AUTOSAR XML (schema 4-2-2)
package /Components
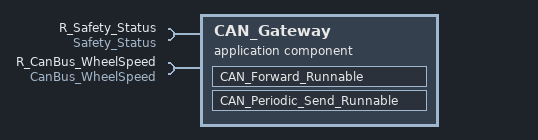
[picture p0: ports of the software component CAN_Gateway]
  application sw component type CAN_Gateway
    provide/require port PR_CAN_Gateway_Interface: provided-required-interface=CAN_Gateway_Interface
    provide/require port PR_BrakeActuator_Service: provided-required-interface=BrakeActuator_Service
    provide/require port PR_SteeringMotor_Service: provided-required-interface=SteeringMotor_Service
    require port R_Safety_Status: required-interface=Safety_Status
    require port R_CanBus_WheelSpeed: required-interface=CanBus_WheelSpeed
    behavior CAN_Gateway_Behavior
      data received event CAN_Rx_Event: start-on-event=CAN_Forward_Runnable
      data send completed event CAN_Tx_Complete: start-on-event=CAN_Periodic_Send_Runnable, event-source=CAN_Tx_Access
      runnable CAN_Forward_Runnable: symbol=Can_Gateway_CAN_Forward_Runnable
        data-receive-point-by-arguments:
          access CAN_Rx_Access: accessed-variable=PR_CAN_Gateway_Interface.CAN_Frame_Rx
        data-send-points:
          access CAN_Tx_Access: accessed-variable=PR_CAN_Gateway_Interface.CAN_Frame_Tx
      runnable CAN_Periodic_Send_Runnable: minimum-start-interval=10, symbol=Can_Gateway_CAN_Periodic_Send_Runnable
        data-receive-point-by-arguments:
          access Periodic_Config_Access: accessed-variable=R_Safety_Status.GatewayConfig
        data-send-points:
          access Periodic_Tx_Access: accessed-variable=PR_CAN_Gateway_Interface.CAN_Frame_Tx
